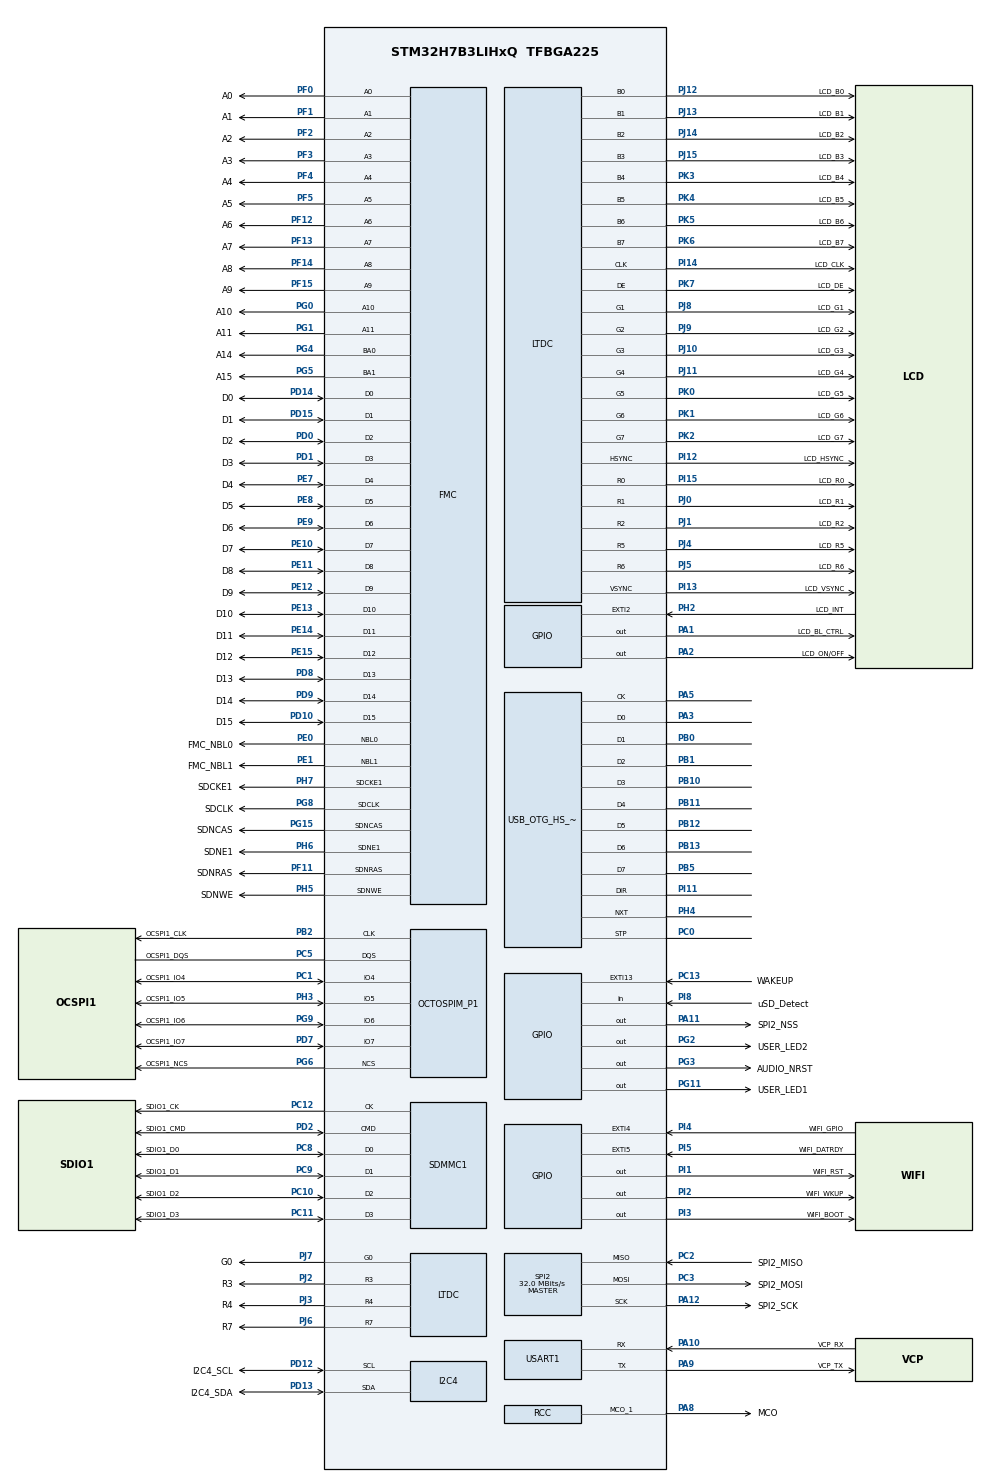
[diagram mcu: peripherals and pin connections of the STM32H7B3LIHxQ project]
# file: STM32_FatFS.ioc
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CORTEX_M7.CPU_DCache=Enabled
CORTEX_M7.CPU_ICache=Enabled
DMA2D.ColorMode=DMA2D_OUTPUT_RGB565
Dma.MEMTOMEM.0.Direction=DMA_MEMORY_TO_MEMORY
Dma.MEMTOMEM.0.EventEnable=DISABLE
Dma.MEMTOMEM.0.FIFOMode=DMA_FIFOMODE_ENABLE
Dma.MEMTOMEM.0.FIFOThreshold=DMA_FIFO_THRESHOLD_FULL
Dma.MEMTOMEM.0.Instance=DMA1_Stream0
Dma.MEMTOMEM.0.MemBurst=DMA_MBURST_SINGLE
Dma.MEMTOMEM.0.MemDataAlignment=DMA_MDATAALIGN_HALFWORD
Dma.MEMTOMEM.0.MemInc=DMA_MINC_ENABLE
Dma.MEMTOMEM.0.Mode=DMA_NORMAL
Dma.MEMTOMEM.0.PeriphBurst=DMA_PBURST_SINGLE
Dma.MEMTOMEM.0.PeriphDataAlignment=DMA_PDATAALIGN_HALFWORD
Dma.MEMTOMEM.0.PeriphInc=DMA_PINC_ENABLE
Dma.MEMTOMEM.0.Polarity=HAL_DMAMUX_REQ_GEN_RISING
Dma.MEMTOMEM.0.Priority=DMA_PRIORITY_MEDIUM
Dma.MEMTOMEM.0.RequestNumber=1
Dma.MEMTOMEM.0.SignalID=NONE
Dma.MEMTOMEM.0.SyncEnable=DISABLE
Dma.MEMTOMEM.0.SyncPolarity=HAL_DMAMUX_SYNC_NO_EVENT
Dma.MEMTOMEM.0.SyncRequestNumber=1
Dma.MEMTOMEM.0.SyncSignalID=NONE
Dma.Request0=MEMTOMEM
FATFS.BSP.number=1
FATFS._CODE_PAGE=437
FATFS._STRF_ENCODE=0
FATFS0.BSP.STBoard=false
FATFS0.BSP.api=Unknown
FATFS0.BSP.i2caddr=0
FATFS0.BSP.instance=PI8
FATFS0.BSP.ip=GPIO
FATFS0.BSP.mode=Input
FATFS0.BSP.name=Detect_SDIO
FATFS0.BSP.solution=PI8
FMC.CASLatency1=FMC_SDRAM_CAS_LATENCY_2
FMC.ColumnBitsNumber1=FMC_SDRAM_COLUMN_BITS_NUM_9
FMC.ExitSelfRefreshDelay1=7
FMC.LoadToActiveDelay1=2
FMC.RCDDelay1=2
FMC.RPDelay1=2
FMC.RPDelay2=2
FMC.ReadBurst1=FMC_SDRAM_RBURST_ENABLE
FMC.ReadBurst2=FMC_SDRAM_RBURST_ENABLE
FMC.ReadPipeDelay1=FMC_SDRAM_RPIPE_DELAY_2
FMC.ReadPipeDelay2=FMC_SDRAM_RPIPE_DELAY_2
FMC.RowCycleDelay1=7
FMC.RowCycleDelay2=7
FMC.SDClockPeriod1=FMC_SDRAM_CLOCK_PERIOD_3
FMC.SDClockPeriod2=FMC_SDRAM_CLOCK_PERIOD_3
FMC.SelfRefreshTime1=4
FMC.WriteRecoveryTime1=3
I2C4.Timing=0xC010151E
LTDC.ActiveH=272
LTDC.ActiveW=480
LTDC.Alpha_L0=255
LTDC.BlendingFactor1_L0=LTDC_BLENDING_FACTOR1_PAxCA
LTDC.BlendingFactor2_L0=LTDC_BLENDING_FACTOR2_PAxCA
LTDC.HBP=43
LTDC.HFP=8
LTDC.HSync=10
LTDC.ImageHeight_L0=272
LTDC.ImageWidth_L0=480
LTDC.Layers=0
LTDC.PixelFormat_L0=LTDC_PIXEL_FORMAT_RGB565
LTDC.VBP=12
LTDC.VFP=4
LTDC.VSync=10
LTDC.WindowX1_L0=480
LTDC.WindowY1_L0=272
Mcu.Family=STM32H7
Mcu.Name=STM32H7B3LIHxQ
Mcu.Package=TFBGA225
NVIC.DMA1_Stream0_IRQn=true\:0\:0\:false\:false\:true\:true\:true
NVIC.OTG_HS_IRQn=true\:0\:0\:false\:false\:true\:true\:true
NVIC.PriorityGroup=NVIC_PRIORITYGROUP_4
NVIC.TIM17_IRQn=true\:0\:0\:false\:false\:true\:false\:true
NVIC.TimeBase=TIM17_IRQn
NVIC.TimeBaseIP=TIM17
OCTOSPI1.MemoryType=HAL_OSPI_MEMTYPE_MACRONIX
PA1.GPIO_Label=LCD_BL_CTRL
PA1.PinState=GPIO_PIN_SET
PA1.Signal=GPIO_Output
PA10.GPIO_Label=VCP_RX
PA10.Mode=Asynchronous
PA10.Signal=USART1_RX
PA11.GPIO_Label=SPI2_NSS
PA11.Signal=GPIO_Output
PA12.GPIO_Label=SPI2_SCK
PA12.Mode=Full_Duplex_Master
PA12.Signal=SPI2_SCK
PA13.GPIO_Label=JTMS
PA13.Mode=JTAG_5_pins
PA13.Signal=DEBUG_JTMS-SWDIO
PA14.GPIO_Label=JTCK
PA14.Mode=JTAG_5_pins
PA14.Signal=DEBUG_JTCK-SWCLK
PA15.GPIO_Label=JTDI
PA15.Mode=JTAG_5_pins
PA15.Signal=DEBUG_JTDI
PA2.GPIO_Label=LCD_ON/OFF
PA2.PinState=GPIO_PIN_SET
PA2.Signal=GPIO_Output
PA3.Mode=Device_HS
PA3.Signal=USB_OTG_HS_ULPI_D0
PA5.Mode=Device_HS
PA5.Signal=USB_OTG_HS_ULPI_CK
PA8.GPIO_Label=MCO
PA8.Mode=Clock-out-1
PA8.Signal=RCC_MCO_1
PA9.GPIO_Label=VCP_TX
PA9.Mode=Asynchronous
PA9.Signal=USART1_TX
PB0.Mode=Device_HS
PB0.Signal=USB_OTG_HS_ULPI_D1
PB1.Mode=Device_HS
PB1.Signal=USB_OTG_HS_ULPI_D2
PB10.Mode=Device_HS
PB10.Signal=USB_OTG_HS_ULPI_D3
PB11.Mode=Device_HS
PB11.Signal=USB_OTG_HS_ULPI_D4
PB12.Mode=Device_HS
PB12.Signal=USB_OTG_HS_ULPI_D5
PB13.Mode=Device_HS
PB13.Signal=USB_OTG_HS_ULPI_D6
PB2.GPIO_Label=OCSPI1_CLK
PB2.Mode=O1_P1_CLK
PB2.Signal=OCTOSPIM_P1_CLK
PB3.GPIO_Label=JTDO_TRACESWO
PB3.Mode=JTAG_5_pins
PB3.Signal=DEBUG_JTDO-SWO
PB4.Mode=JTAG_5_pins
PB4.Signal=DEBUG_JTRST
PB5.Mode=Device_HS
PB5.Signal=USB_OTG_HS_ULPI_D7
PC0.Mode=Device_HS
PC0.Signal=USB_OTG_HS_ULPI_STP
PC1.GPIO_Label=OCSPI1_IO4
PC1.Mode=OCTOSPI1_IOL_Port1H
PC1.Signal=OCTOSPIM_P1_IO4
PC10.GPIO_Label=SDIO1_D2
PC10.Mode=SD_4_bits_Wide_bus
PC10.Signal=SDMMC1_D2
PC11.GPIO_Label=SDIO1_D3
PC11.Mode=SD_4_bits_Wide_bus
PC11.Signal=SDMMC1_D3
PC12.GPIO_Label=SDIO1_CK
PC12.Mode=SD_4_bits_Wide_bus
PC12.Signal=SDMMC1_CK
PC13.GPIO_Label=WAKEUP
PC13.Signal=GPXTI13
PC14-OSC32_IN.Mode=LSE-External-Oscillator
PC14-OSC32_IN.Signal=RCC_OSC32_IN
PC15-OSC32_OUT.Mode=LSE-External-Oscillator
PC15-OSC32_OUT.Signal=RCC_OSC32_OUT
PC2.GPIO_Label=SPI2_MISO
PC2.Mode=Full_Duplex_Master
PC2.Signal=SPI2_MISO
PC3.GPIO_Label=SPI2_MOSI
PC3.Mode=Full_Duplex_Master
PC3.Signal=SPI2_MOSI
PC5.GPIO_Label=OCSPI1_DQS
PC5.Mode=OCTOSPI1_Port1_DQS
PC5.Signal=OCTOSPIM_P1_DQS
PC8.GPIO_Label=SDIO1_D0
PC8.Mode=SD_4_bits_Wide_bus
PC8.Signal=SDMMC1_D0
PC9.GPIO_Label=SDIO1_D1
PC9.Mode=SD_4_bits_Wide_bus
PC9.Signal=SDMMC1_D1
PD0.GPIO_Label=D2
PD0.Signal=FMC_D2_DA2
PD1.GPIO_Label=D3
PD1.Signal=FMC_D3_DA3
PD10.GPIO_Label=D15
PD10.Signal=FMC_D15_DA15
PD12.GPIO_Label=I2C4_SCL
PD12.Mode=I2C
PD12.Signal=I2C4_SCL
PD13.GPIO_Label=I2C4_SDA
PD13.Mode=I2C
PD13.Signal=I2C4_SDA
PD14.GPIO_Label=D0
PD14.Signal=FMC_D0_DA0
PD15.GPIO_Label=D1
PD15.Signal=FMC_D1_DA1
PD2.GPIO_Label=SDIO1_CMD
PD2.Mode=SD_4_bits_Wide_bus
PD2.Signal=SDMMC1_CMD
PD7.GPIO_Label=OCSPI1_IO7
PD7.Mode=OCTOSPI1_IOL_Port1H
PD7.Signal=OCTOSPIM_P1_IO7
PD8.GPIO_Label=D13
PD8.Signal=FMC_D13_DA13
PD9.GPIO_Label=D14
PD9.Signal=FMC_D14_DA14
PE0.GPIO_Label=FMC_NBL0
PE0.Signal=FMC_NBL0
PE1.GPIO_Label=FMC_NBL1
PE1.Signal=FMC_NBL1
PE10.GPIO_Label=D7
PE10.Signal=FMC_D7_DA7
PE11.GPIO_Label=D8
PE11.Signal=FMC_D8_DA8
PE12.GPIO_Label=D9
PE12.Signal=FMC_D9_DA9
PE13.GPIO_Label=D10
PE13.Signal=FMC_D10_DA10
PE14.GPIO_Label=D11
PE14.Signal=FMC_D11_DA11
PE15.GPIO_Label=D12
PE15.Signal=FMC_D12_DA12
PE7.GPIO_Label=D4
PE7.Signal=FMC_D4_DA4
PE8.GPIO_Label=D5
PE8.Signal=FMC_D5_DA5
PE9.GPIO_Label=D6
PE9.Signal=FMC_D6_DA6
PF0.GPIO_Label=A0
PF0.Signal=FMC_A0
PF1.GPIO_Label=A1
PF1.Signal=FMC_A1
PF11.GPIO_Label=SDNRAS
PF11.Signal=FMC_SDNRAS
PF12.GPIO_Label=A6
PF12.Signal=FMC_A6
PF13.GPIO_Label=A7
PF13.Signal=FMC_A7
PF14.GPIO_Label=A8
PF14.Signal=FMC_A8
PF15.GPIO_Label=A9
PF15.Signal=FMC_A9
PF2.GPIO_Label=A2
PF2.Signal=FMC_A2
PF3.GPIO_Label=A3
PF3.Signal=FMC_A3
PF4.GPIO_Label=A4
PF4.Signal=FMC_A4
PF5.GPIO_Label=A5
PF5.Signal=FMC_A5
PG0.GPIO_Label=A10
PG0.Signal=FMC_A10
PG1.GPIO_Label=A11
PG1.Signal=FMC_A11
PG11.GPIO_Label=USER_LED1
PG11.Signal=GPIO_Output
PG14.Signal=EVENTOUT
PG15.GPIO_Label=SDNCAS
PG15.Signal=FMC_SDNCAS
PG2.GPIO_Label=USER_LED2
PG2.Signal=GPIO_Output
PG3.GPIO_Label=AUDIO_NRST
PG3.PinState=GPIO_PIN_SET
PG3.Signal=GPIO_Output
PG4.GPIO_Label=A14
PG4.Signal=FMC_A14_BA0
PG5.GPIO_Label=A15
PG5.Signal=FMC_A15_BA1
PG6.GPIO_Label=OCSPI1_NCS
PG6.Mode=OCTOSPI1_Port1_NCS
PG6.Signal=OCTOSPIM_P1_NCS
PG8.GPIO_Label=SDCLK
PG8.Signal=FMC_SDCLK
PG9.GPIO_Label=OCSPI1_IO6
PG9.Mode=OCTOSPI1_IOL_Port1H
PG9.Signal=OCTOSPIM_P1_IO6
PH0-OSC_IN.Mode=HSE-External-Oscillator
PH0-OSC_IN.Signal=RCC_OSC_IN
PH1-OSC_OUT.Mode=HSE-External-Oscillator
PH1-OSC_OUT.Signal=RCC_OSC_OUT
PH2.GPIO_Label=LCD_INT
PH2.Signal=GPXTI2
PH3.GPIO_Label=OCSPI1_IO5
PH3.Mode=OCTOSPI1_IOL_Port1H
PH3.Signal=OCTOSPIM_P1_IO5
PH4.Mode=Device_HS
PH4.Signal=USB_OTG_HS_ULPI_NXT
PH5.GPIO_Label=SDNWE
PH5.Signal=FMC_SDNWE
PH6.GPIO_Label=SDNE1
PH6.Mode=SdramChipSelect2_1
PH6.Signal=FMC_SDNE1
PH7.GPIO_Label=SDCKE1
PH7.Mode=SdramChipSelect2_1
PH7.Signal=FMC_SDCKE1
PI1.GPIO_Label=WIFI_RST
PI1.Signal=GPIO_Output
PI11.Mode=Device_HS
PI11.Signal=USB_OTG_HS_ULPI_DIR
PI12.GPIO_Label=LCD_HSYNC
PI12.Mode=RGB888
PI12.Signal=LTDC_HSYNC
PI13.GPIO_Label=LCD_VSYNC
PI13.Mode=RGB888
PI13.Signal=LTDC_VSYNC
PI14.GPIO_Label=LCD_CLK
PI14.Mode=RGB888
PI14.Signal=LTDC_CLK
PI15.GPIO_Label=LCD_R0
PI15.Mode=RGB888
PI15.Signal=LTDC_R0
PI2.GPIO_Label=WIFI_WKUP
PI2.Signal=GPIO_Output
PI3.GPIO_Label=WIFI_BOOT
PI3.Signal=GPIO_Output
PI4.GPIO_Label=WIFI_GPIO
PI4.Signal=GPXTI4
PI5.GPIO_Label=WIFI_DATRDY
PI5.Signal=GPXTI5
PI8.GPIO_Label=uSD_Detect
PI8.Signal=GPIO_Input
PJ0.GPIO_Label=LCD_R1
PJ0.Mode=RGB888
PJ0.Signal=LTDC_R1
PJ1.GPIO_Label=LCD_R2
PJ1.Mode=RGB888
PJ1.Signal=LTDC_R2
PJ10.GPIO_Label=LCD_G3
PJ10.Mode=RGB888
PJ10.Signal=LTDC_G3
PJ11.GPIO_Label=LCD_G4
PJ11.Mode=RGB888
PJ11.Signal=LTDC_G4
PJ12.GPIO_Label=LCD_B0
PJ12.Mode=RGB888
PJ12.Signal=LTDC_B0
PJ13.GPIO_Label=LCD_B1
PJ13.Mode=RGB888
PJ13.Signal=LTDC_B1
PJ14.GPIO_Label=LCD_B2
PJ14.Mode=RGB888
PJ14.Signal=LTDC_B2
PJ15.GPIO_Label=LCD_B3
PJ15.Mode=RGB888
PJ15.Signal=LTDC_B3
PJ2.GPIO_Label=R3
PJ2.Mode=RGB888
PJ2.Signal=LTDC_R3
PJ3.GPIO_Label=R4
PJ3.Mode=RGB888
PJ3.Signal=LTDC_R4
PJ4.GPIO_Label=LCD_R5
PJ4.Mode=RGB888
PJ4.Signal=LTDC_R5
PJ5.GPIO_Label=LCD_R6
PJ5.Mode=RGB888
PJ5.Signal=LTDC_R6
PJ6.GPIO_Label=R7
PJ6.Mode=RGB888
PJ6.Signal=LTDC_R7
PJ7.GPIO_Label=G0
PJ7.Mode=RGB888
PJ7.Signal=LTDC_G0
PJ8.GPIO_Label=LCD_G1
PJ8.Mode=RGB888
PJ8.Signal=LTDC_G1
PJ9.GPIO_Label=LCD_G2
PJ9.Mode=RGB888
PJ9.Signal=LTDC_G2
PK0.GPIO_Label=LCD_G5
PK0.Mode=RGB888
PK0.Signal=LTDC_G5
PK1.GPIO_Label=LCD_G6
PK1.Mode=RGB888
PK1.Signal=LTDC_G6
PK2.GPIO_Label=LCD_G7
PK2.Mode=RGB888
PK2.Signal=LTDC_G7
PK3.GPIO_Label=LCD_B4
PK3.Mode=RGB888
PK3.Signal=LTDC_B4
PK4.GPIO_Label=LCD_B5
PK4.Mode=RGB888
PK4.Signal=LTDC_B5
PK5.GPIO_Label=LCD_B6
PK5.Mode=RGB888
PK5.Signal=LTDC_B6
PK6.GPIO_Label=LCD_B7
PK6.Mode=RGB888
PK6.Signal=LTDC_B7
PK7.GPIO_Label=LCD_DE
PK7.Mode=RGB888
PK7.Signal=LTDC_DE
ProjectManager.HeapSize=0x2000
ProjectManager.StackSize=0x2000
ProjectManager.TargetToolchain=STM32CubeIDE
RCC.ADCFreq_Value=200000000
RCC.APB1Freq_Value=70000000
RCC.APB2Freq_Value=70000000
RCC.APB3Freq_Value=70000000
RCC.APB4Freq_Value=70000000
RCC.CDPPRE=RCC_APB3_DIV2
RCC.CDPPRE1=RCC_APB1_DIV2
RCC.CDPPRE2=RCC_APB2_DIV2
RCC.CortexFreq_Value=280000000
RCC.DIVM1=12
RCC.DIVM2=12
RCC.DIVM3=24
RCC.DIVN1=280
RCC.DIVN2=200
RCC.DIVN3=192
RCC.DIVP3=4
RCC.DIVQ1=14
RCC.DIVQ3=4
RCC.DIVR1=4
RCC.DIVR2=4
RCC.DIVR3=20
RCC.FMCCLockSelection=RCC_FMCCLKSOURCE_PLL2
RCC.HCLKFreq_Value=140000000
RCC.HPRE=RCC_HCLK_DIV2
RCC.PLL2FRACN=0
RCC.PLL3FRACN=0
RCC.PLLFRACN=0
RCC.PLLSourceVirtual=RCC_PLLSOURCE_HSE
RCC.PWR_Regulator_Voltage_Scale=PWR_REGULATOR_VOLTAGE_SCALE0
RCC.QSPICLockSelection=RCC_OSPICLKSOURCE_PLL2
RCC.RCC_MCO1Source=RCC_MCO1SOURCE_HSE
RCC.RTCClockSelection=RCC_RTCCLKSOURCE_LSE
RCC.SDMMC1CLockSelection=RCC_SDMMCCLKSOURCE_PLL2
RCC.SPI123CLockSelection=RCC_SPI123CLKSOURCE_CLKP
RCC.SRDPPRE=RCC_APB4_DIV2
RCC.SYSCLKFreq_VALUE=280000000
RCC.SYSCLKSource=RCC_SYSCLKSOURCE_PLLCLK
RCC.SupplySource=PWR_DIRECT_SMPS_SUPPLY
RCC.USBCLockSelection=RCC_USBCLKSOURCE_PLL3
RCC.USBFreq_Value=48000000
SH.FMC_A0.0=FMC_A0,12b-sda1
SH.FMC_A1.0=FMC_A1,12b-sda1
SH.FMC_A10.0=FMC_A10,12b-sda1
SH.FMC_A11.0=FMC_A11,12b-sda1
SH.FMC_A14_BA0.0=FMC_BA0,FourSdramBanks1
SH.FMC_A15_BA1.0=FMC_BA1,FourSdramBanks1
SH.FMC_A2.0=FMC_A2,12b-sda1
SH.FMC_A3.0=FMC_A3,12b-sda1
SH.FMC_A4.0=FMC_A4,12b-sda1
SH.FMC_A5.0=FMC_A5,12b-sda1
SH.FMC_A6.0=FMC_A6,12b-sda1
SH.FMC_A7.0=FMC_A7,12b-sda1
SH.FMC_A8.0=FMC_A8,12b-sda1
SH.FMC_A9.0=FMC_A9,12b-sda1
SH.FMC_D0_DA0.0=FMC_D0,sd-16b-d1
SH.FMC_D10_DA10.0=FMC_D10,sd-16b-d1
SH.FMC_D11_DA11.0=FMC_D11,sd-16b-d1
SH.FMC_D12_DA12.0=FMC_D12,sd-16b-d1
SH.FMC_D13_DA13.0=FMC_D13,sd-16b-d1
SH.FMC_D14_DA14.0=FMC_D14,sd-16b-d1
SH.FMC_D15_DA15.0=FMC_D15,sd-16b-d1
SH.FMC_D1_DA1.0=FMC_D1,sd-16b-d1
SH.FMC_D2_DA2.0=FMC_D2,sd-16b-d1
SH.FMC_D3_DA3.0=FMC_D3,sd-16b-d1
SH.FMC_D4_DA4.0=FMC_D4,sd-16b-d1
SH.FMC_D5_DA5.0=FMC_D5,sd-16b-d1
SH.FMC_D6_DA6.0=FMC_D6,sd-16b-d1
SH.FMC_D7_DA7.0=FMC_D7,sd-16b-d1
SH.FMC_D8_DA8.0=FMC_D8,sd-16b-d1
SH.FMC_D9_DA9.0=FMC_D9,sd-16b-d1
SH.FMC_NBL0.0=FMC_NBL0,Sd2ByteEnable1
SH.FMC_NBL1.0=FMC_NBL1,Sd2ByteEnable1
SH.FMC_SDCLK.0=FMC_SDCLK,12b-sda1
SH.FMC_SDNCAS.0=FMC_SDNCAS,12b-sda1
SH.FMC_SDNRAS.0=FMC_SDNRAS,12b-sda1
SH.FMC_SDNWE.0=FMC_SDNWE,12b-sda1
SPI2.CalculateBaudRate=32.0 MBits/s
SPI2.Direction=SPI_DIRECTION_2LINES
SPI2.Mode=SPI_MODE_MASTER
SPI2.VirtualType=VM_MASTER
USART1.VirtualMode-Asynchronous=VM_ASYNC
USB_OTG_HS.Sof_enable-Device_HS=ENABLE
USB_OTG_HS.VirtualMode-Device_HS=Device_HS
VP_DMA2D_VS_DMA2D.Mode=DMA2D_Activate
VP_FATFS_VS_Generic.Mode=User_defined
VP_FATFS_VS_SDIO.Mode=SDIO
VP_OCTOSPI1_VS_octo.Mode=octo_mode
VP_RNG_VS_RNG.Mode=RNG_Activate
VP_RTC_VS_RTC_Activate.Mode=RTC_Enabled
VP_SYS_VS_tim17.Mode=TIM17
board=STM32H7B3I-DK

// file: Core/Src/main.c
/* USER CODE BEGIN Header */
/**
  ******************************************************************************
  * @file           : main.c
  * @brief          : Main program body
  ******************************************************************************
  * @attention
  *
  * <h2><center>&copy; Copyright (c) 2021 STMicroelectronics.
  * All rights reserved.</center></h2>
  *
  * This software component is licensed by ST under BSD 3-Clause license,
  * the "License"; You may not use this file except in compliance with the
  * License. You may obtain a copy of the License at:
  *                        opensource.org/licenses/BSD-3-Clause
  *
  ******************************************************************************
  */
/* USER CODE END Header */
#include "main.h"
#include "dma.h"
#include "dma2d.h"
#include "fatfs.h"
#include "i2c.h"
#include "ltdc.h"
#include "octospi.h"
#include "rng.h"
#include "rtc.h"
#include "sdmmc.h"
#include "spi.h"
#include "usart.h"
#include "usb_otg.h"
#include "gpio.h"
#include "fmc.h"

void SystemClock_Config(void);

int main(void)
{

  /* Enable I-Cache---------------------------------------------------------*/
  SCB_EnableICache();

  /* Enable D-Cache---------------------------------------------------------*/
  SCB_EnableDCache();

  /* MCU Configuration--------------------------------------------------------*/

  /* Reset of all peripherals, Initializes the Flash interface and the Systick. */
  HAL_Init();

  /* Configure the system clock */
  SystemClock_Config();

  /* Initialize all configured peripherals */
  MX_GPIO_Init();
  MX_DMA_Init();
  MX_FMC_Init();
  MX_I2C4_Init();
  MX_LTDC_Init();
  MX_OCTOSPI1_Init();
  MX_RTC_Init();
  MX_SDMMC1_SD_Init();
  MX_SPI2_Init();
  MX_USART1_UART_Init();
  MX_USB_OTG_HS_PCD_Init();
  MX_DMA2D_Init();
  MX_RNG_Init();
  MX_FATFS_Init();
  /* USER CODE BEGIN 2 */
  FRESULT res;
  uint8_t tx[] = "This is STM32 working with FatFs using SD card as storage medium";
  uint8_t rx[100] = "0";

  UINT cnt;

  res = f_mount(&SDFatFS, (TCHAR const*) SDPath, 0);
  res = f_mount(&USERFatFS, (TCHAR const*) USERPath, 0);

  /*only first time*/
  //res = f_mkfs((TCHAR const*) SDPath, FM_ANY, 0, buffer, sizeof(buffer));

  //res = f_mkdir("STM32");

  res = f_open(&USERFile, "0:STM32/stm32.txt", FA_CREATE_ALWAYS | FA_WRITE);
  res = f_write(&USERFile, tx, sizeof(tx), &cnt);
  res = f_close(&USERFile);

  res = f_open(&USERFile, "1:STM32/stm32_1.txt", FA_CREATE_ALWAYS | FA_WRITE);
  res = f_write(&USERFile, tx, sizeof(tx), &cnt);
  res = f_close(&USERFile);

  res = f_open(&USERFile, "0:STM32/stm32_2.txt", FA_CREATE_ALWAYS | FA_WRITE);
  res = f_write(&USERFile, tx, sizeof(tx), &cnt);
  res = f_close(&USERFile);

  res = f_open(&USERFile, "1:STM32/stm32_3.txt", FA_CREATE_ALWAYS | FA_WRITE);
  res = f_write(&USERFile, tx, sizeof(tx), &cnt);
  res = f_close(&USERFile);

  res = f_open(&USERFile, "STM32_4.txt", FA_CREATE_ALWAYS | FA_WRITE);
  res = f_write(&USERFile, tx, sizeof(tx), &cnt);
  res = f_close(&USERFile);

  res = f_open(&USERFile, "STM32/stm32_5.txt", FA_CREATE_ALWAYS | FA_WRITE);
  res = f_write(&USERFile, tx, sizeof(tx), &cnt);
  res = f_close(&USERFile);

  res = f_open(&USERFile, "STM32/stm32_6.txt", FA_CREATE_ALWAYS | FA_WRITE);
  res = f_write(&USERFile, tx, sizeof(tx), &cnt);
  res = f_close(&USERFile);

  res = f_open(&USERFile, "STM32/stm32_7.txt", FA_CREATE_ALWAYS | FA_WRITE);
  res = f_write(&USERFile, tx, sizeof(tx), &cnt);
  res = f_close(&USERFile);

  ///////////////////////////////////////////////
  res = f_open(&USERFile, "STM32/stm32_2.txt", FA_READ);
  res = f_read(&USERFile, rx, sizeof(rx), &cnt);
  res = f_close(&USERFile);

  FATFS *fs;
  DWORD fre_clust, fre_sect, tot_sect;

  /* Get volume information and free clusters of drive 1 */
  res = f_getfree(SDPath, &fre_clust, &fs);

  /* Get total sectors and free sectors */
  tot_sect = (fs->n_fatent - 2) * fs->csize;
  fre_sect = fre_clust * fs->csize;

  /* Print the free space (assuming 512 bytes/sector) */
  char temp_buffer[100];
  sprintf(temp_buffer, "%10lu KiB total drive space.\n%10lu KiB available.\n", tot_sect / 2, fre_sect / 2);

  res = f_mount(NULL, (TCHAR const*) SDPath, 0);

  (void)res;
  /* USER CODE END 2 */

  /* Infinite loop */
  while (1)
  {

  }
}

void SystemClock_Config(void)
{
  RCC_OscInitTypeDef RCC_OscInitStruct = {0};
  RCC_ClkInitTypeDef RCC_ClkInitStruct = {0};
  RCC_PeriphCLKInitTypeDef PeriphClkInitStruct = {0};

  /** Supply configuration update enable
  */
  HAL_PWREx_ConfigSupply(PWR_DIRECT_SMPS_SUPPLY);
  /** Configure the main internal regulator output voltage
  */
  __HAL_PWR_VOLTAGESCALING_CONFIG(PWR_REGULATOR_VOLTAGE_SCALE0);

  while(!__HAL_PWR_GET_FLAG(PWR_FLAG_VOSRDY)) {}
  /** Configure LSE Drive Capability
  */
  HAL_PWR_EnableBkUpAccess();
  __HAL_RCC_LSEDRIVE_CONFIG(RCC_LSEDRIVE_LOW);
  /** Macro to configure the PLL clock source
  */
  __HAL_RCC_PLL_PLLSOURCE_CONFIG(RCC_PLLSOURCE_HSE);
  /** Initializes the RCC Oscillators according to the specified parameters
  * in the RCC_OscInitTypeDef structure.
  */
  RCC_OscInitStruct.OscillatorType = RCC_OSCILLATORTYPE_HSI48|RCC_OSCILLATORTYPE_HSI
                              |RCC_OSCILLATORTYPE_HSE|RCC_OSCILLATORTYPE_LSE;
  RCC_OscInitStruct.HSEState = RCC_HSE_ON;
  RCC_OscInitStruct.LSEState = RCC_LSE_ON;
  RCC_OscInitStruct.HSIState = RCC_HSI_DIV1;
  RCC_OscInitStruct.HSICalibrationValue = RCC_HSICALIBRATION_DEFAULT;
  RCC_OscInitStruct.HSI48State = RCC_HSI48_ON;
  RCC_OscInitStruct.PLL.PLLState = RCC_PLL_ON;
  RCC_OscInitStruct.PLL.PLLSource = RCC_PLLSOURCE_HSE;
  RCC_OscInitStruct.PLL.PLLM = 12;
  RCC_OscInitStruct.PLL.PLLN = 280;
  RCC_OscInitStruct.PLL.PLLP = 2;
  RCC_OscInitStruct.PLL.PLLQ = 14;
  RCC_OscInitStruct.PLL.PLLR = 4;
  RCC_OscInitStruct.PLL.PLLRGE = RCC_PLL1VCIRANGE_1;
  RCC_OscInitStruct.PLL.PLLVCOSEL = RCC_PLL1VCOWIDE;
  RCC_OscInitStruct.PLL.PLLFRACN = 0;
  if (HAL_RCC_OscConfig(&RCC_OscInitStruct) != HAL_OK)
  {
    Error_Handler();
  }
  /** Initializes the CPU, AHB and APB buses clocks
  */
  RCC_ClkInitStruct.ClockType = RCC_CLOCKTYPE_HCLK|RCC_CLOCKTYPE_SYSCLK
                              |RCC_CLOCKTYPE_PCLK1|RCC_CLOCKTYPE_PCLK2
                              |RCC_CLOCKTYPE_D3PCLK1|RCC_CLOCKTYPE_D1PCLK1;
  RCC_ClkInitStruct.SYSCLKSource = RCC_SYSCLKSOURCE_PLLCLK;
  RCC_ClkInitStruct.SYSCLKDivider = RCC_SYSCLK_DIV1;
  RCC_ClkInitStruct.AHBCLKDivider = RCC_HCLK_DIV2;
  RCC_ClkInitStruct.APB3CLKDivider = RCC_APB3_DIV2;
  RCC_ClkInitStruct.APB1CLKDivider = RCC_APB1_DIV2;
  RCC_ClkInitStruct.APB2CLKDivider = RCC_APB2_DIV2;
  RCC_ClkInitStruct.APB4CLKDivider = RCC_APB4_DIV2;

  if (HAL_RCC_ClockConfig(&RCC_ClkInitStruct, FLASH_LATENCY_3) != HAL_OK)
  {
    Error_Handler();
  }
  PeriphClkInitStruct.PeriphClockSelection = RCC_PERIPHCLK_RTC|RCC_PERIPHCLK_LTDC
                              |RCC_PERIPHCLK_USART16|RCC_PERIPHCLK_RNG
                              |RCC_PERIPHCLK_SPI2|RCC_PERIPHCLK_SDMMC
                              |RCC_PERIPHCLK_I2C4|RCC_PERIPHCLK_USB
                              |RCC_PERIPHCLK_OSPI|RCC_PERIPHCLK_FMC
                              |RCC_PERIPHCLK_CKPER;
  PeriphClkInitStruct.PLL2.PLL2M = 12;
  PeriphClkInitStruct.PLL2.PLL2N = 200;
  PeriphClkInitStruct.PLL2.PLL2P = 2;
  PeriphClkInitStruct.PLL2.PLL2Q = 2;
  PeriphClkInitStruct.PLL2.PLL2R = 4;
  PeriphClkInitStruct.PLL2.PLL2RGE = RCC_PLL2VCIRANGE_1;
  PeriphClkInitStruct.PLL2.PLL2VCOSEL = RCC_PLL2VCOWIDE;
  PeriphClkInitStruct.PLL2.PLL2FRACN = 0;
  PeriphClkInitStruct.PLL3.PLL3M = 24;
  PeriphClkInitStruct.PLL3.PLL3N = 192;
  PeriphClkInitStruct.PLL3.PLL3P = 4;
  PeriphClkInitStruct.PLL3.PLL3Q = 4;
  PeriphClkInitStruct.PLL3.PLL3R = 20;
  PeriphClkInitStruct.PLL3.PLL3RGE = RCC_PLL3VCIRANGE_0;
  PeriphClkInitStruct.PLL3.PLL3VCOSEL = RCC_PLL3VCOMEDIUM;
  PeriphClkInitStruct.PLL3.PLL3FRACN = 0;
  PeriphClkInitStruct.FmcClockSelection = RCC_FMCCLKSOURCE_PLL2;
  PeriphClkInitStruct.OspiClockSelection = RCC_OSPICLKSOURCE_PLL2;
  PeriphClkInitStruct.SdmmcClockSelection = RCC_SDMMCCLKSOURCE_PLL2;
  PeriphClkInitStruct.CkperClockSelection = RCC_CLKPSOURCE_HSI;
  PeriphClkInitStruct.Spi123ClockSelection = RCC_SPI123CLKSOURCE_CLKP;
  PeriphClkInitStruct.Usart16ClockSelection = RCC_USART16910CLKSOURCE_D2PCLK2;
  PeriphClkInitStruct.RngClockSelection = RCC_RNGCLKSOURCE_HSI48;
  PeriphClkInitStruct.UsbClockSelection = RCC_USBCLKSOURCE_PLL3;
  PeriphClkInitStruct.I2c4ClockSelection = RCC_I2C4CLKSOURCE_D3PCLK1;
  PeriphClkInitStruct.RTCClockSelection = RCC_RTCCLKSOURCE_LSE;
  if (HAL_RCCEx_PeriphCLKConfig(&PeriphClkInitStruct) != HAL_OK)
  {
    Error_Handler();
  }
  HAL_RCC_MCOConfig(RCC_MCO1, RCC_MCO1SOURCE_HSE, RCC_MCODIV_1);
}

 /**
  * @brief  Period elapsed callback in non blocking mode
  * @note   This function is called  when TIM17 interrupt took place, inside
  * HAL_TIM_IRQHandler(). It makes a direct call to HAL_IncTick() to increment
  * a global variable "uwTick" used as application time base.
  * @param  htim : TIM handle
  * @retval None
  */
void HAL_TIM_PeriodElapsedCallback(TIM_HandleTypeDef *htim)
{
  if (htim->Instance == TIM17) {
    HAL_IncTick();
  }
}

void Error_Handler(void)
{
  __disable_irq();
  while (1)
  {
  }
}

/************************ (C) COPYRIGHT STMicroelectronics *****END OF FILE****/
